# DSS_RCM register map
Vendor: Texas Instruments
Peripheral module from a debugger description file (folder awr2x44p).
Registers are 32-bit, read-write, no defined reset value unless marked. A register's access mark holds for its fields unless they carry their own. Offsets are as the file gives them; lines under a group give offsets from that group; [hi:lo] are bit positions; {n}, {i} and the like mark numbered series; 'fields as' and 'values as' point back to an identical list; <NAME> marks a mode.

## DSS_RCM
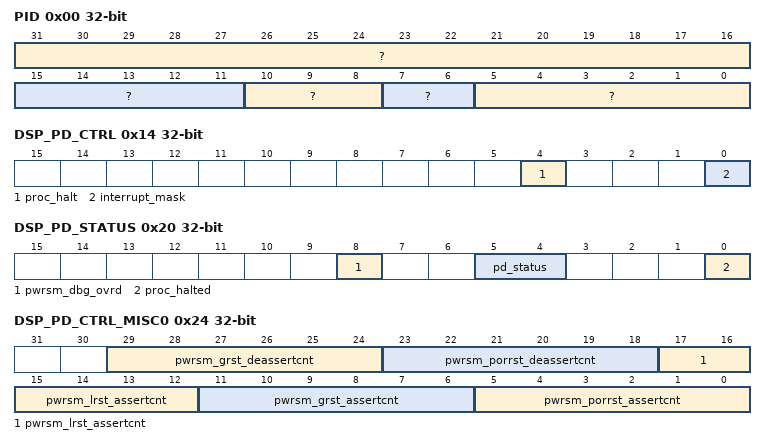
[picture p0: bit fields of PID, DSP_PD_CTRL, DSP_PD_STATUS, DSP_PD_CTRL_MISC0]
0x00 PID ro
  [31:16] ?, [15:11] ?, [10:8] ?, [7:6] ?, [5:0] ?
0x04 HW_REG0
  [31:0] hwreg — HW Reserved regiser
0x08 HW_REG1
  [31:0] hwreg — HW Reserved regiser
0x0C PREVIOUS_NAME
  [31:0] hwreg — HW Reserved regiser
0x10 HW_REG3
  [31:0] hwreg — HW Reserved regiser
0x14 DSP_PD_CTRL
  [4] proc_halt — Controls the unhalting on the processor during the power-up sequence Write 1 : The DSP is kept in halt state at the end of the power up sequence. The L2 memories can now be initialised and loaded before setting this bit to 0, unhalting the processor and begin execution Write 0 : The processor is unhalted at the end of the power up sequence. Here the assumption is the code is already downloaded in L2 and the processor can immediatey being execution on power up.
  [0] interrupt_mask — Masks interrupts to the DSP. Write 1 : Mask interrupts to the DSP before powering off the DSP. When masked, any interrupts are now stored in the Missed event register. Write 0 : Send the interrupts to the DSP after power on.
0x18 DSP_PD_TRIGGER_WAKUP
  [0] wakeup_trigger — Write pulse bit field: Trigger Power Up of the DSP. Write 1 : Triggers DSP power up sequence
0x1C DSP_PD_TRIGGER_SLEEP
  [0] sleep_trigger — Write pulse bit field: Trigger Power Down of the DSP. Write 1 : Triggers DSP power down sequence
0x20 DSP_PD_STATUS ro
  [8] pwrsm_dbg_ovrd — Status bit indicating if there is an override for the DSP from Debug SubSystem. 0 : No override from DebugSS 1 : Override from DebugSS
  [5:4] pd_status — Power Mode status of DSP 00 : Powered OFF 01 : Transitioning from OFF to ON state 10 : Transitioning from ON to OFF state 11 : Powered ON
  [0] proc_halted — Processor is halted
0x24 DSP_PD_CTRL_MISC0
  [29:24] pwrsm_grst_deassertcnt — TI Internal Feature No of cycles to wait after de-assertion of GRSTN during DSP Power-up sequence. Max allowed value is 31.
  [23:18] pwrsm_porrst_deassertcnt — TI Internal Feature No of cycles to wait after de-assertion of POR during DSP Power-up sequence. Max allowed value is 31.
  [17:12] pwrsm_lrst_assertcnt — TI Internal Feature No of cycles to wait after assertion of LRSTN during DSP Power-up sequence. Max allowed value is 31.
  [11:6] pwrsm_grst_assertcnt — TI Internal Feature No of cycles to wait after assertion of GRSTN during DSP Power-up sequence. Max allowed value is 31.
  [5:0] pwrsm_porrst_assertcnt — TI Internal Feature No of cycles to wait after assertion of POR during DSP Power-up sequence. Max allowed value is 31.
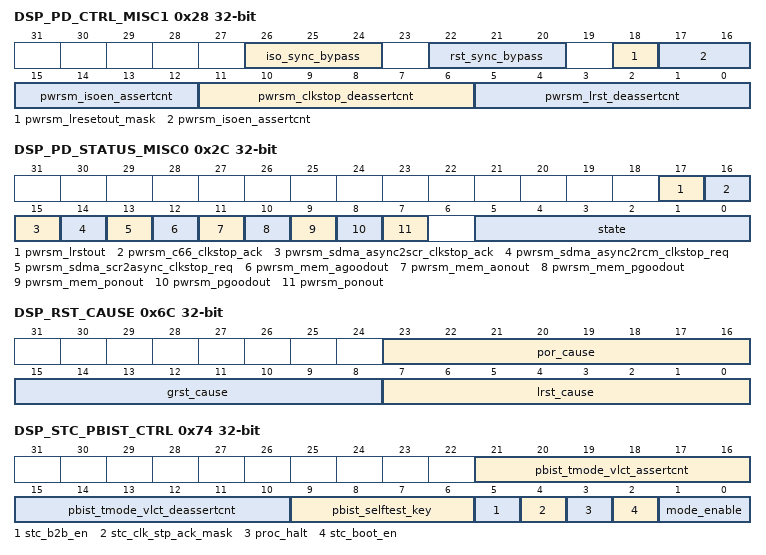
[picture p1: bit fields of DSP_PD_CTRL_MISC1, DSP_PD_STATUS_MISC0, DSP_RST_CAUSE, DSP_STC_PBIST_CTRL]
0x28 DSP_PD_CTRL_MISC1
  [26:24] iso_sync_bypass — HW RnD reserved. Do not Touch - Only for debug purpose
  [22:20] rst_sync_bypass — HW RnD reserved. Do not Touch - Only for debug purpose
  [18] pwrsm_lresetout_mask — TI Internal Feature 1:mask lresetout from DSPin FSM
  [17:12] pwrsm_isoen_assertcnt — TI Internal Feature No of cycles to wait after assertion of ISO_ENABLE during GEM power-down sequence. Max allowed value is 31.
  [11:6] pwrsm_clkstop_deassertcnt — TI Internal Feature No of cycles to wait after de-assertion of GEM_CLK_STOP_REQ during GEM Power-up sequence. Max allowed value is 31.
  [5:0] pwrsm_lrst_deassertcnt — TI Internal Feature No of cycles to wait after de-assertion of LRSTN during DSP Power-up sequence. Max allowed value is 31.
0x2C DSP_PD_STATUS_MISC0 ro
  [17] pwrsm_lrstout — TI Internal Feature Lreset output indication from GEM
  [16] pwrsm_c66_clkstop_ack — TI Internal Feature Clock stop request ack from GEM
  [15] pwrsm_sdma_async2scr_clkstop_ack — TI Internal Feature SDMA slave disable Done from clock stop ack from the master port of the async bridge present in the SDMA port.
  [14] pwrsm_sdma_async2rcm_clkstop_req — TI Internal Feature SDMA Slave disable Ack from Interconnect. This is from the clock stop req signal coming from the slave port of the async bridge in SDMA.
  [13] pwrsm_sdma_scr2async_clkstop_req — TI Internal Feature Clock Stop request from SCR to SDMA Async Bridge
  [12] pwrsm_mem_agoodout — TI Internal Feature Memory AGOOD Output from GEM (synchronized to Bus clock)
  [11] pwrsm_mem_aonout — TI Internal Feature Memory AON Output from GEM (synchronized to Bus clock)
  [10] pwrsm_mem_pgoodout — TI Internal Feature Memory PGOOD Output from DSP (synchronized to Bus clock)
  [9] pwrsm_mem_ponout — TI Internal Feature Memory PON Output from DSP (synchronized to Bus clock)
  [8] pwrsm_pgoodout — TI Internal Feature Logic PGOOD Output from DSP (synchronized to Bus clock)
  [7] pwrsm_ponout — TI Internal Feature Logic PON Output from DSP (synchronized to Bus clock)
  [5:0] state — This is the internal state of the DSP power State machine. Curretnly value of 13 needs to be polled to confirm we we can now download code to the L2 memory before unhalting the processor. Plan to change this in TPR and provide a single bit to poll on and move this to debug register since all the other states are irrelevant for SW
0x30 DSP_PD_WAKEUP_MASK0
  [31:0] wakeup_mask0 — Bit level mask for each of the wakeup source bits [31:0] 1 : Masked 0 : Unmasked
0x34 DSP_PD_WAKEUP_MASK1
  [31:0] wakeup_mask1 — Bit level mask for each of the wakeup source bits [63:32] 1 : Masked 0 : Unmasked.
0x38 DSP_PD_WAKEUP_MASK2
  [31:0] wakeup_mask2 — Bit level mask for each of the wakeup source bits [95:64] 1 : Masked 0 : Unmasked.
{0x3C+4i} DSP_PD_WAKEUP_STATUS{i} ro (i=0..2)
  [31:0] wakeup_status{i} — Wakeup source status bits [{32i+31}:{32i}]
{0x48+4i} DSP_PD_WAKEUP_STATUS{i}_CLR (i=0..2)
  [31:0] wakeup_status{i}_clr — Write pulse bit field: Clear bit for wakeup source status bits [{32i+31}:{32i}]. Write 0x1 to clear the corrsponding status bit : Its a wspecial access type, write to this field will generate a pulse
{0x54+4i} DSP_PD_MISSED_EVENT_MASK{i} (i=0..2)
  [31:0] missed_event_mask{i} — Bit level mask for each of the missed events before getting pushed into DSP. Corresponds to Event lines[{32i+31}:{32i}] 1 : Masked 0 : Unmasked.
0x60 DSP_PD_MISSED_EVENT_STATUS0 ro
  [31:0] missed_event_status0 — Missed events monitor status for interrupts [31:0]. Interrupts to DSP that are masked by INTERRUPT_MASK register field are captured in this register
0x64 DSP_PD_MISSED_EVENT_STATUS1 ro
  [31:0] missed_event_status1 — Missed events monitor status for interrupts [63:32] Interrupts to DSP that are masked by INTERRUPT_MASK register field are captured in this register
0x68 DSP_PD_MISSED_EVENT_STATUS2 ro
  [31:0] missed_event_status2 — Missed events monitor status for interrupts [95:64] Interrupts to DSP that are masked by INTERRUPT_MASK register field are captured in this register
0x6C DSP_RST_CAUSE ro
  [23:16] por_cause — DSP POR reset Bitwise Indication : Bit 0 : Por Reset Bit 1 : Sub system Reset from TOPRCM Bit 2 : Reset from DSS_RCM::DSS_DSP_RST_CTRL Bit 3 : Reset from Power FSM Bit 4 : Reset from STC FSM
  [15:8] grst_cause — DSP Greset Bitwise Indication : Bit 0 : Por Reset Bit 1 : Sub system Reset from TOPRCM Bit 2 : Reset from DSS_RCM::DSS_DSP_RST_CTRL Bit 3 : Reset from Power FSM Bit 4 : Reset from STC FSM
  [7:0] lrst_cause — DSP Lreset Bitwise Indication : Bit 0 : Por Reset Bit 1 : Sub system Reset from TOPRCM Bit 2 : Reset from DSS_RCM::DSS_DSP_RST_CTRL Bit 3 : Reset from Debugss Bit 4 : Reset from Power FSM Bit 5 : Reset from STC FSM
0x70 DSP_RST_CAUSE_CLR
  [0] clear — Write pulse bit field: Write 0x1 to clear the reset cause register for any previous resets : Its a wspecial access type, write to this field will generate a pulse
0x74 DSP_STC_PBIST_CTRL
  [21:16] pbist_tmode_vlct_assertcnt — No of clocks (in terms of 200 MHz DSPSS Bus clock) after asserting GEM TMODE VLCT signal before proceeding to the next state. Max allowed value is 31.
  [15:10] pbist_tmode_vlct_deassertcnt — No of clocks (in terms of 200 MHz DSPSS Bus clock) after De-asserting GEM TMODE VLCT signal before proceeding to the next state. Max allowed value is 31.
  [9:6] pbist_selftest_key — [4:1] DSP PBIST SELFTEST KEY = 4'b1010
  [5] stc_b2b_en — Enables back to Back STC.Needs to be set to 1 for self test
  [4] stc_clk_stp_ack_mask — Mask bit for ignoring the clock stop ack from GEM. This will be used for ignoring clock stop ack during boot-up. 1 --> Ignore clock stop ack from GEM. 0 --> Wait for clock stop ack from GEM after giving clock stop request.
  [3] proc_halt — Configuration to halt the state machine before the final de-assertion of LRST to enable program download. 1 --> Halt, 0 --> Proceed.
  [2] stc_boot_en — Enable GEM STC during GEM power UP
  [1:0] mode_enable — Enable for PBIST and STC. 00 - Reserved, 01 --> STC only 10 --> PBIST only 11 --> PBIST followed by STC
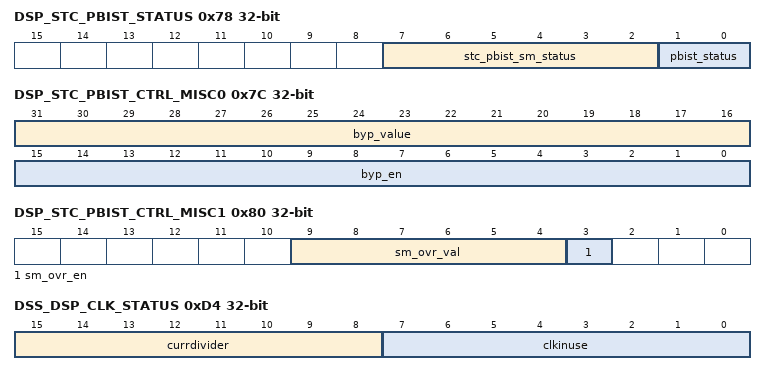
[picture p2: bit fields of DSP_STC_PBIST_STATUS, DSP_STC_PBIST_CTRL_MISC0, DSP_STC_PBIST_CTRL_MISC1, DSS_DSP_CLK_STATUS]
0x78 DSP_STC_PBIST_STATUS ro
  [7:2] stc_pbist_sm_status — PBIST status from GEM. undefined - Fail Indication undefined - Done indication
  [1:0] pbist_status — Current state of STC PBIST state machine
0x7C DSP_STC_PBIST_CTRL_MISC0
  [31:16] byp_value — DSP PBIST STC misc Control
  [15:0] byp_en — DSP PBIST STC misc Control
0x80 DSP_STC_PBIST_CTRL_MISC1
  [9:4] sm_ovr_val — TI Internal Register.Reserved for HW RnD
  [3] sm_ovr_en — TI Internal Register.Reserved for HW RnD
0x84 DSP_STC_PBIST_START
  [0] sm_trig — write pulse bit field: Write pulse bit field: Trigger pulse for the STC PBIST state machine. This is a self-clearing pulse. : Its a wspecial access type, write to this field will generate a pulse
0x88 DSP_STC_PBIST_STATUS_CLR
  [0] clear — Write pulse bit field: Clear bit for PBIST Status : Its a wspecial access type, write to this field will generate a pulse
0x8C DSS_DSP_CLK_SRC_SEL
  [11:0] clksrcsel — Select line for selecting source clock for DSS DSP. Data should be loaded as multibit. For example: if Clock source 0x5 should be selected then 0x555 should be configured to the register. Refer to TPR12 clock spec for source clock reference
0x90 DSS_HWA_CLK_SRC_SEL
  [2:0] clksrcsel — Select line for selecting source clock for DSS HWA. Data should be loaded as multibit. Write 3'b000 : TOPRCM_CR5_CLK Write 3'b111 : TOPRCM_SYS_CLK
0x94 DSS_RTIA_CLK_SRC_SEL
  [11:0] clksrcsel — Select line for selecting source clock for DSS_RTIA. Data should be loaded as multibit. For example: if Clock source 0x5 should be selected then 0x555 should be configured to the register. Refer to TPR12 clock spec for source clock reference
0x98 DSS_RTIB_CLK_SRC_SEL
  [11:0] clksrcsel — Select line for selecting source clock for DSS RTIB. Data should be loaded as multibit. For example: if Clock source 0x5 should be selected then 0x555 should be configured to the register. Refer to TPR12 clock spec for source clock reference
0x9C DSS_WDT_CLK_SRC_SEL
  [11:0] clksrcsel — Select line for selecting source clock for DSS Watchdog. Data should be loaded as multibit. For example: if Clock source 0x5 should be selected then 0x555 should be configured to the register. Refer to TPR12 clock spec for source clock reference
0xA0 DSS_SCIA_CLK_SRC_SEL
  [11:0] clksrcsel — Select line for selecting source clock for DSS SCIA. Data should be loaded as multibit. For example: if Clock source 0x5 should be selected then 0x555 should be configured to the register. Refer to TPR12 clock spec for source clock reference
0xA4 DSS_DSP_CLK_DIV_VAL
  [11:0] clkdiv — Divider value for DSS DSP selected clock. Data should be loaded as multibit. For example: if divider value of 0x5 should be selected then 0x555 should be configured to the register.
0xA8 DSS_RTIA_CLK_DIV_VAL
  [11:0] clkdiv — Divider value for DSS RTIA selected clock. Data should be loaded as multibit. For example: if divider value of 0x5 should be selected then 0x555 should be configured to the register.
0xAC DSS_RTIB_CLK_DIV_VAL
  [11:0] clkdiv — Divider value for DSS RTIB selected clock. Data should be loaded as multibit. For example: if divider value of 0x5 should be selected then 0x555 should be configured to the register.
0xB0 DSS_WDT_CLK_DIV_VAL
  [11:0] clkdiv — Divider value for DSS Watchdog selected clock. Data should be loaded as multibit. For example: if divider value of 0x5 should be selected then 0x555 should be configured to the register.
0xB4 DSS_SCIA_CLK_DIV_VAL
  [11:0] clkdiv — Divider value for DSS SCIA selected clock. Data should be loaded as multibit. For example: if divider value of 0x5 should be selected then 0x555 should be configured to the register.
0xB8 DSS_DSP_CLK_GATE
  [2:0] gated — Clock gatring config for DSS DSP. Data should be loaded as multibit. Write 3'b000 : Clock is ungated Write 3'b111 : Clock is gated
0xBC DSS_HWA_CLK_GATE
  [2:0] gated — Clock gatring config for DSS HWA Data should be loaded as multibit. Write 3'b000 : Clock is ungated Write 3'b111 : Clock is gated
0xC0 DSS_RTIA_CLK_GATE
  [2:0] gated — Clock gatring config for DSS RTA Data should be loaded as multibit. Write 3'b000 : Clock is ungated Write 3'b111 : Clock is gated
0xC4 DSS_RTIB_CLK_GATE
  [2:0] gated — Clock gatring config for DSS RTIB Data should be loaded as multibit. Write 3'b000 : Clock is ungated Write 3'b111 : Clock is gated
0xC8 DSS_WDT_CLK_GATE
  [2:0] gated — Clock gatring config for DSS Watchdog Data should be loaded as multibit. Write 3'b000 : Clock is ungated Write 3'b111 : Clock is gated
0xCC DSS_SCIA_CLK_GATE
  [2:0] gated — Clock gatring config for DSS SCIA Data should be loaded as multibit. Write 3'b000 : Clock is ungated Write 3'b111 : Clock is gated
0xD0 DSS_CBUFF_CLK_GATE
  [2:0] gated — Clock gating config for DSS CBUFF Data should be loaded as multibit. Write 3'b000 : Clock is ungated Write 3'b111 : Clock is gated
0xD4 DSS_DSP_CLK_STATUS ro
  [15:8] currdivider — Status shows the current divider value choosen for DSS DSP Clock
  [7:0] clkinuse — Status shows the source clock slected for DSS DSP Clock
0xD8 DSS_HWA_CLK_STATUS ro
  [1:0] clkinuse — Status shows the source clock slected for DSS HWA Clock
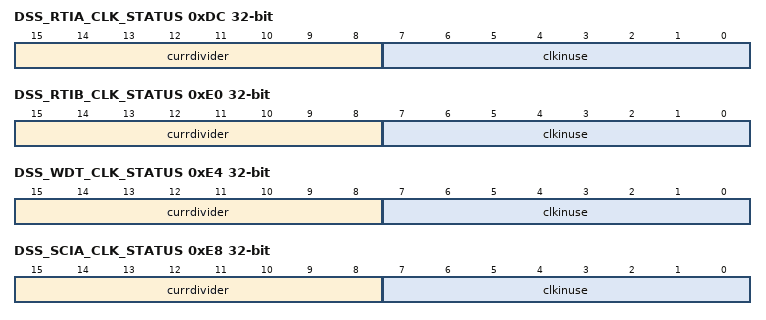
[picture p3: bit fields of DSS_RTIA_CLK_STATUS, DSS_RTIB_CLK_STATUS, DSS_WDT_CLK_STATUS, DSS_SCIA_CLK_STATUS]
0xDC DSS_RTIA_CLK_STATUS ro
  [15:8] currdivider — Status shows the current divider value choosen for DSS RTIA Clock
  [7:0] clkinuse — Status shows the source clock slected for DSS RTIA Clock
0xE0 DSS_RTIB_CLK_STATUS ro
  [15:8] currdivider — Status shows the current divider value choosen for DSS RTIB Clock
  [7:0] clkinuse — Status shows the source clock slected for DSS RTIB Clock
0xE4 DSS_WDT_CLK_STATUS ro
  [15:8] currdivider — Status shows the current divider value choosen for DSS Watchdog Clock
  [7:0] clkinuse — Status shows the source clock slected for DSS Watchdog Clock
0xE8 DSS_SCIA_CLK_STATUS ro
  [15:8] currdivider — Status shows the current divider value choosen for DSS SCIA Clock
  [7:0] clkinuse — Status shows the source clock slected for DSS SCIA Clock
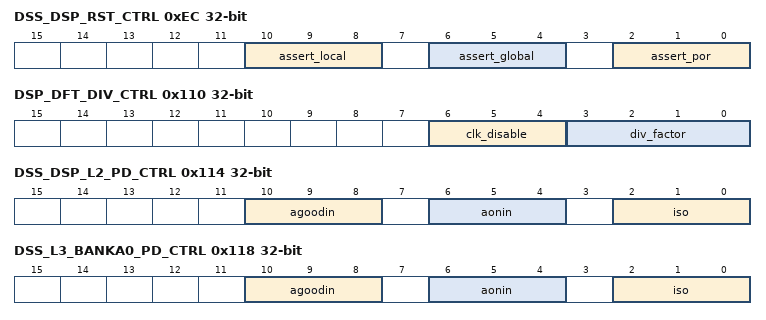
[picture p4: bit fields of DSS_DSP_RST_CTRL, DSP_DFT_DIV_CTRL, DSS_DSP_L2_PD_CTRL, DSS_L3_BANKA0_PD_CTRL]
0xEC DSS_DSP_RST_CTRL
  [10:8] assert_local — Local Reset control for DSS DSP Data should be loaded as multibit. Write 3'b000: Reset is not asserted by SW. There could be another reset source which could reset the module. Refer to RCM spec for more details Write 3'b111 : Reset is asserted by SW
  [6:4] assert_global — Global Reset control forDSS DSP Data should be loaded as multibit. Write 3'b000: Reset is not asserted by SW. There could be another reset source which could reset the module. Refer to RCM spec for more details Write 3'b111 : Reset is asserted by SW
  [2:0] assert_por — Power on Reset control for DSS DSP Data should be loaded as multibit. Write 3'b000: Reset is not asserted by SW. There could be another reset source which could reset the module. Refer to RCM spec for more details Write 3'b111 : Reset is asserted by SW
0xF0 DSS_ESM_RST_CTRL
  [2:0] assert — This feature is for debug purpose only. Software needs to ensure the state of Device/IP before configuring. Writing 3'b11 will assert reset for DSS ESM
0xF4 DSS_SCIA_RST_CTRL
  [2:0] assert — This feature is for debug purpose only. Software needs to ensure the state of Device/IP before configuring. Writing 3'b11 will assert reset for DSS SCIA
0xF8 DSS_RTIA_RST_CTRL
  [2:0] assert — This feature is for debug purpose only. Software needs to ensure the state of Device/IP before configuring. Writing 3'b11 will assert reset for DSS RTIA
0xFC DSS_RTIB_RST_CTRL
  [2:0] assert — This feature is for debug purpose only. Software needs to ensure the state of Device/IP before configuring. Writing 3'b11 will assert reset for DSS RTIB
0x100 DSS_WDT_RST_CTRL
  [2:0] assert — This feature is for debug purpose only. Software needs to ensure the state of Device/IP before configuring. Writing 3'b11 will assert reset for DSS Watchdog
0x104 DSS_DCCA_RST_CTRL
  [2:0] assert — This feature is for debug purpose only. Software needs to ensure the state of Device/IP before configuring. Writing 3'b11 will assert reset for DSS DCCA
0x108 DSS_DCCB_RST_CTRL
  [2:0] assert — This feature is for debug purpose only. Software needs to ensure the state of Device/IP before configuring. Writing 3'b11 will assert reset for DSS DCCB
0x10C DSS_MCRC_RST_CTRL
  [2:0] assert — This feature is for debug purpose only. Software needs to ensure the state of Device/IP before configuring. Writing 3'b11 will assert reset for DSS MCRC
0x110 DSP_DFT_DIV_CTRL
  [6:4] clk_disable — DSP DFT Control for clock_disable. Multibit implementation. Write 0x0 to enable Write 0x7 to diable
  [3:0] div_factor — DSP DFT Control for div factor
0x114 DSS_DSP_L2_PD_CTRL
  [10:8] agoodin — SW Control for <IP>_PD_CTRL Memory Array Power up CRTL1
  [6:4] aonin — SW Control for <IP>_PD_CTRL Memory Array Power up CRTL0
  [2:0] iso — SW Control for <IP>_PD_CTRL Isolation
0x118 DSS_L3_BANKA0_PD_CTRL
  fields as DSS_DSP_L2_PD_CTRL
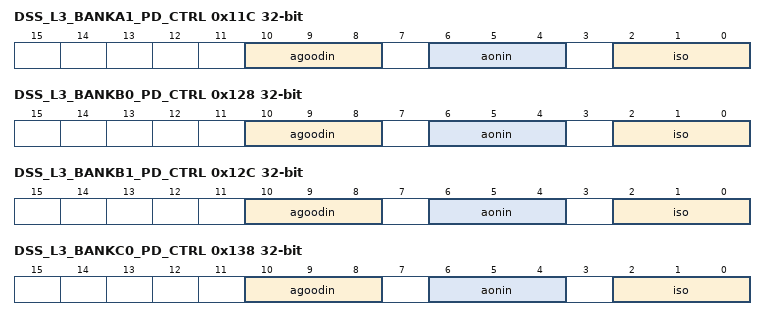
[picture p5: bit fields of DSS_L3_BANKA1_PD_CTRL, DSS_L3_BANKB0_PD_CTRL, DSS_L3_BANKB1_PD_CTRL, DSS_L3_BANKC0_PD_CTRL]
0x11C DSS_L3_BANKA1_PD_CTRL
  fields as DSS_DSP_L2_PD_CTRL
0x128 DSS_L3_BANKB0_PD_CTRL
  fields as DSS_DSP_L2_PD_CTRL
0x12C DSS_L3_BANKB1_PD_CTRL
  fields as DSS_DSP_L2_PD_CTRL
0x138 DSS_L3_BANKC0_PD_CTRL
  fields as DSS_DSP_L2_PD_CTRL
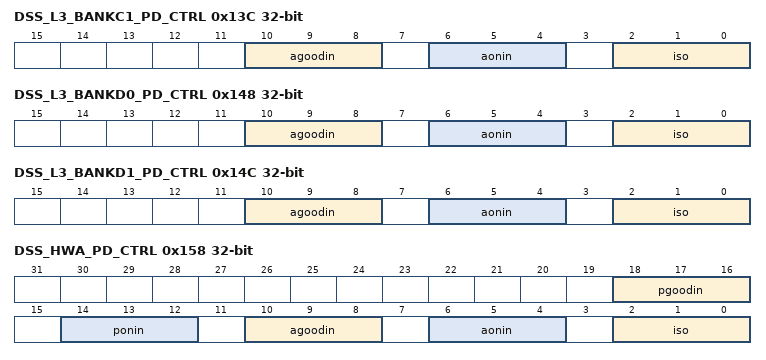
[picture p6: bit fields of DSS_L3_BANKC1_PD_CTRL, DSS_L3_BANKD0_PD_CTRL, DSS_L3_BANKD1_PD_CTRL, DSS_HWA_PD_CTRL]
0x13C DSS_L3_BANKC1_PD_CTRL
  fields as DSS_DSP_L2_PD_CTRL
0x148 DSS_L3_BANKD0_PD_CTRL
  fields as DSS_DSP_L2_PD_CTRL
0x14C DSS_L3_BANKD1_PD_CTRL
  fields as DSS_DSP_L2_PD_CTRL
0x158 DSS_HWA_PD_CTRL
  [18:16] pgoodin — SW Control for <IP>_PD_CTRL Power up CRTL1
  [14:12] ponin — SW Control for <IP>_PD_CTRL Power up CRTL0
  [10:8] agoodin — SW Control for <IP>_PD_CTRL Memory Array Power up CRTL1
  [6:4] aonin — SW Control for <IP>_PD_CTRL Memory Array Power up CRTL0
  [2:0] iso — SW Control for <IP>_PD_CTRL Isolation
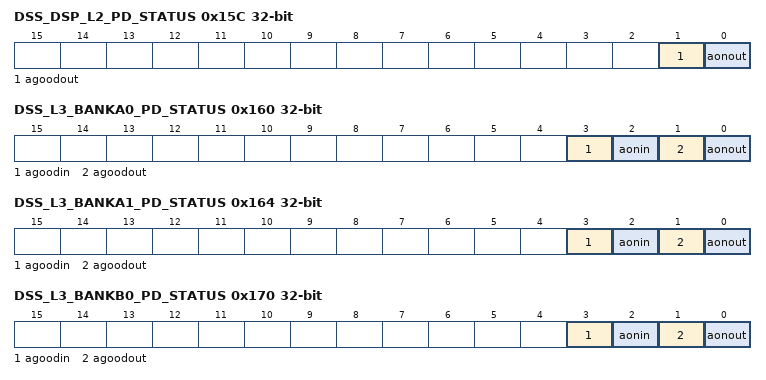
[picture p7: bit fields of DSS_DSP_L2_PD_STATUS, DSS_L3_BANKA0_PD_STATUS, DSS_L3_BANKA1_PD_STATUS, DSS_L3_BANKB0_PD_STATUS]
0x15C DSS_DSP_L2_PD_STATUS ro
  [1] agoodout — Status for <IP>_PD_CTRL Memory Array Power up CRTL1
  [0] aonout — Status for <IP>_PD_CTRL Memory Array Power up CRTL0
0x160 DSS_L3_BANKA0_PD_STATUS ro
  [3] agoodin — Status for sticky control <IP>_PD_CTRL Memory Array Power up CRTL1
  [2] aonin — Status for sticky control <IP>_PD_CTRL Memory Array Power up CRTL0
  [1] agoodout — Status for <IP>_PD_CTRL Memory Array Power up CRTL1
  [0] aonout — Status for <IP>_PD_CTRL Memory Array Power up CRTL0
0x164 DSS_L3_BANKA1_PD_STATUS ro
  fields as DSS_L3_BANKA0_PD_STATUS
0x170 DSS_L3_BANKB0_PD_STATUS ro
  fields as DSS_L3_BANKA0_PD_STATUS
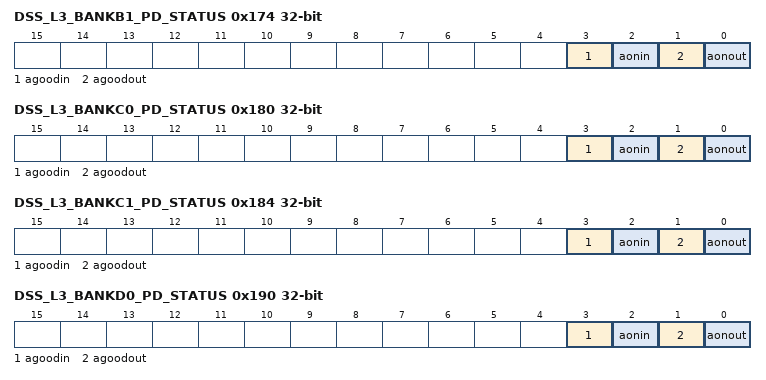
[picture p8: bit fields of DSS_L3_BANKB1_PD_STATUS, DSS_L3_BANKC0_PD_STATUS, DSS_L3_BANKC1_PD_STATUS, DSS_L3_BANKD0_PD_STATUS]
0x174 DSS_L3_BANKB1_PD_STATUS ro
  fields as DSS_L3_BANKA0_PD_STATUS
0x180 DSS_L3_BANKC0_PD_STATUS ro
  fields as DSS_L3_BANKA0_PD_STATUS
0x184 DSS_L3_BANKC1_PD_STATUS ro
  fields as DSS_L3_BANKA0_PD_STATUS
0x190 DSS_L3_BANKD0_PD_STATUS ro
  fields as DSS_L3_BANKA0_PD_STATUS
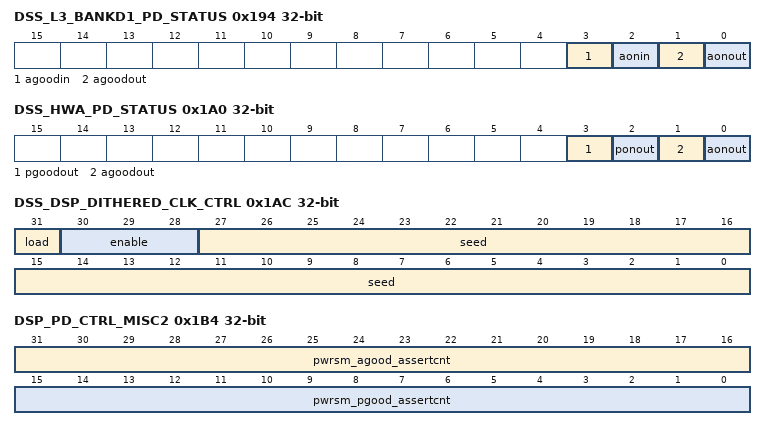
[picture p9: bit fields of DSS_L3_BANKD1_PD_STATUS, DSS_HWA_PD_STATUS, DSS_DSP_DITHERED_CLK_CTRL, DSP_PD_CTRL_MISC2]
0x194 DSS_L3_BANKD1_PD_STATUS ro
  fields as DSS_L3_BANKA0_PD_STATUS
0x1A0 DSS_HWA_PD_STATUS ro
  [3] pgoodout — Status for <IP>_PD_CTRL Power up CRTL1
  [2] ponout — Status for <IP>_PD_CTRL Power up CRTL0
  [1] agoodout — Status for <IP>_PD_CTRL Memory Array Power up CRTL1
  [0] aonout — Status for <IP>_PD_CTRL Memory Array Power up CRTL0
0x1A4 DSS_DSP_TRCCLK_DIVRATIO
  [3:0] divratio — DSP Trace Clock Divide Ratio
0x1A8 DSS_DSP_TCLK_DIVRATIO
  [3:0] divratio — DSP TCLK Divide Ratio
0x1AC DSS_DSP_DITHERED_CLK_CTRL
  [31] load — Write pulse bit field: DSP Dithered Clock LFSR Load
  [30:28] enable — DSP Dithered Clock Enable. Write 3'b000 : Disabled Write 3'b111 : Enabled
  [27:0] seed — DSP Dithered Clock LFSR Seed
0x1B0 DSS_L3_PD_CTRL_STICKYBIT
  [2:0] set — Sticky bit for DSS L3 PD CTRL. Write 3'b111 to lock the configuration of DSS_L3_BANK*_PD_CTRL. Once this field is writen, there is no impact of changing the value of aonin and agoodin fields in DSS_L3_BANK*_PD_CTRL registers
0x1B4 DSP_PD_CTRL_MISC2
  [31:16] pwrsm_agood_assertcnt — Value of agood asertion delay
  [15:0] pwrsm_pgood_assertcnt — Value of pgood asertion delay
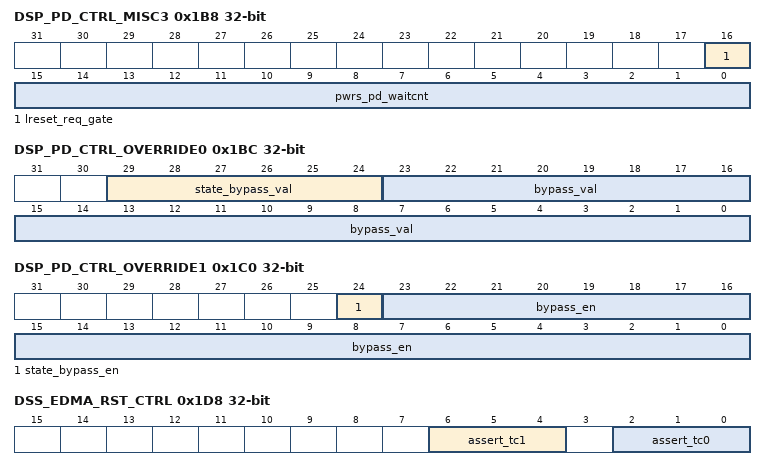
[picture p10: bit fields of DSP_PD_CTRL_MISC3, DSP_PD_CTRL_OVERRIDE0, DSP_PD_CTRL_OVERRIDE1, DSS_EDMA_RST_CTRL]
0x1B8 DSP_PD_CTRL_MISC3
  [16] lreset_req_gate — Gate the lreset request from GEM. For debug purpose.
  [15:0] pwrs_pd_waitcnt — Value of power down wait delay
0x1BC DSP_PD_CTRL_OVERRIDE0
  [29:24] state_bypass_val — DSS DSP power FSM state bypass control. For debug pupose.
  [23:0] bypass_val — DSS DSP power FSM bypass control. For debug pupose.
0x1C0 DSP_PD_CTRL_OVERRIDE1
  [24] state_bypass_en — DSS DSP power FSM state bypass control enable.For debug pupose.
  [23:0] bypass_en — DSS DSP power FSM bypass control enable.For debug pupose.
0x1C4 DSP_PD_CTRL_OVERRIDE2
  [2:0] override_enable — DSS DSP power FSM override enable .For debug pupose.
0x1C8 DSS_HWA_RST_CTRL
  [2:0] assert — This register is for Debug Purposes only. Reset control for DSS HWA Data should be loaded as multibit. Write 3'b000: Reset is not asserted by SW. There could be another reset source which could reset the module. Refer to RCM spec for more details Write 3'b111 : Reset is asserted by SW
0x1CC DSS_HWA_RST_CTRL
  [2:0] assert — This register is for Debug Purposes only. Reset control for DSS TPCCA Data should be loaded as multibit. Write 3'b000: Reset is not asserted by SW. There could be another reset source which could reset the module. Refer to RCM spec for more details Write 3'b111 : Reset is asserted by SW
0x1D0 DSS_EDMA_RST_CTRL
  [2:0] assert — This register is for Debug Purposes only. Reset control for DSS TPCCB Data should be loaded as multibit. Write 3'b000: Reset is not asserted by SW. There could be another reset source which could reset the module. Refer to RCM spec for more details Write 3'b111 : Reset is asserted by SW
0x1D4 DSS_EDMA_RST_CTRL
  [2:0] assert — This register is for Debug Purposes only. Reset control for DSS TPCCC Data should be loaded as multibit. Write 3'b000: Reset is not asserted by SW. There could be another reset source which could reset the module. Refer to RCM spec for more details Write 3'b111 : Reset is asserted by SW
0x1D8 DSS_EDMA_RST_CTRL
  [6:4] assert_tc1 — This register is for Debug Purposes only. Reset control for DSS TPTCA1 Data should be loaded as multibit. Write 3'b000: Reset is not asserted by SW. There could be another reset source which could reset the module. Refer to RCM spec for more details Write 3'b111 : Reset is asserted by SW
  [2:0] assert_tc0 — This register is for Debug Purposes only. Reset control for DSS TPTCA0 Data should be loaded as multibit. Write 3'b000: Reset is not asserted by SW. There could be another reset source which could reset the module. Refer to RCM spec for more details Write 3'b111 : Reset is asserted by SW
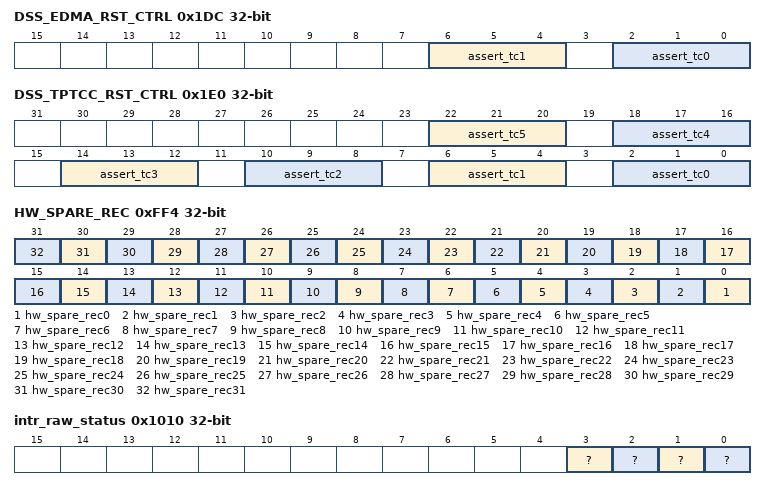
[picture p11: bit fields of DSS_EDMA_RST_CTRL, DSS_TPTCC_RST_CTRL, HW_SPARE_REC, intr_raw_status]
0x1DC DSS_EDMA_RST_CTRL
  [6:4] assert_tc1 — This register is for Debug Purposes only. Reset control for DSS TPTCB1 Data should be loaded as multibit. Write 3'b000: Reset is not asserted by SW. There could be another reset source which could reset the module. Refer to RCM spec for more details Write 3'b111 : Reset is asserted by SW
  [2:0] assert_tc0 — This register is for Debug Purposes only. Reset control for DSS TPTCB0 Data should be loaded as multibit. Write 3'b000: Reset is not asserted by SW. There could be another reset source which could reset the module. Refer to RCM spec for more details Write 3'b111 : Reset is asserted by SW
0x1E0 DSS_TPTCC_RST_CTRL
  [22:20] assert_tc5 — This register is for Debug Purposes only. Reset control for DSS TPTCC1 Data should be loaded as multibit. Write 3'b000: Reset is not asserted by SW. There could be another reset source which could reset the module. Refer to RCM spec for more details Write 3'b111 : Reset is asserted by SW
  [18:16] assert_tc4 — This register is for Debug Purposes only. Reset control for DSS TPTCC0 Data should be loaded as multibit. Write 3'b000: Reset is not asserted by SW. There could be another reset source which could reset the module. Refer to RCM spec for more details Write 3'b111 : Reset is asserted by SW
  [14:12] assert_tc3 — This register is for Debug Purposes only. Reset control for DSS TPTCC1 Data should be loaded as multibit. Write 3'b000: Reset is not asserted by SW. There could be another reset source which could reset the module. Refer to RCM spec for more details Write 3'b111 : Reset is asserted by SW
  [10:8] assert_tc2 — This register is for Debug Purposes only. Reset control for DSS TPTCC0 Data should be loaded as multibit. Write 3'b000: Reset is not asserted by SW. There could be another reset source which could reset the module. Refer to RCM spec for more details Write 3'b111 : Reset is asserted by SW
  [6:4] assert_tc1 — This register is for Debug Purposes only. Reset control for DSS TPTCC1 Data should be loaded as multibit. Write 3'b000: Reset is not asserted by SW. There could be another reset source which could reset the module. Refer to RCM spec for more details Write 3'b111 : Reset is asserted by SW
  [2:0] assert_tc0 — This register is for Debug Purposes only. Reset control for DSS TPTCC0 Data should be loaded as multibit. Write 3'b000: Reset is not asserted by SW. There could be another reset source which could reset the module. Refer to RCM spec for more details Write 3'b111 : Reset is asserted by SW
{0xFD0+4i} HW_SPARE_RW{i} (i=0..3)
  [31:0] hw_spare_rw{i} — Reserved for HW R&D
{0xFE0+4i} HW_SPARE_RO{i} ro (i=0..3)
  [31:0] hw_spare_ro{i} — Reserved for HW R&D
0xFF0 HW_SPARE_WPH
  [31:0] hw_spare_wph — write pulse bit field:Reserved for HW R&D
0xFF4 HW_SPARE_REC
  [n] hw_spare_rec{n} (n=0..31) — Rising Edge Capture reg (write 1 to clear): Reserved for HW R&D
0x1008 LOCK0_KICK0 — - KICK0 component
  [31:0] ?
0x100C LOCK0_KICK1 — - KICK1 component
  [31:0] ?
0x1010 intr_raw_status — Interrupt Raw Status/Set Register
  [3] ? — Proxy0 access violation error. Raw status is read. Write a 1 to set the status. Writing a 0 has no effect.
  [2] ? — Kick access violation error. Raw status is read. Write a 1 to set the status. Writing a 0 has no effect.
  [1] ? — Addressing violation error. Raw status is read. Write a 1 to set the status. Writing a 0 has no effect.
  [0] ? — Protection violation error. Raw status is read. Write a 1 to set the status. Writing a 0 has no effect.
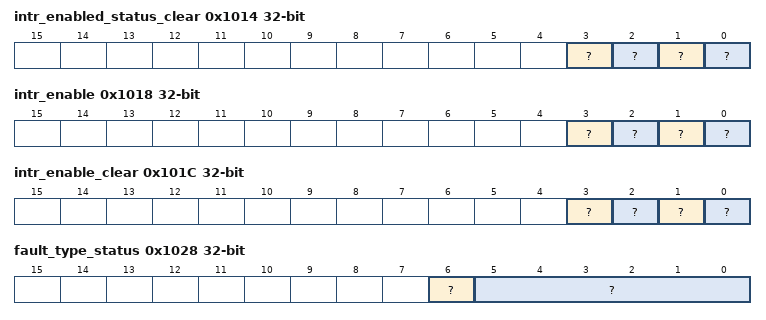
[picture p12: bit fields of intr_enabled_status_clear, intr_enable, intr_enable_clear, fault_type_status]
0x1014 intr_enabled_status_clear — Interrupt Enabled Status/Clear register
  [3] ? — Proxy0 access violation error. Enabled status is read. Write a 1 to clear the status. Writing a 0 has no effect.
  [2] ? — Kick access violation error. Enabled status is read. Write a 1 to clear the status. Writing a 0 has no effect.
  [1] ? — Addressing violation error. Enabled status is read. Write a 1 to clear the status. Writing a 0 has no effect.
  [0] ? — Protection violation error. Enabled status is read. Write a 1 to clear the status. Writing a 0 has no effect.
0x1018 intr_enable — Interrupt Enable register
  [3] ? — Proxy0 access violation error enable. Write a 1 to set the enable. Writing a 0 has no effect.
  [2] ? — Kick access violation error enable. Write a 1 to set the enable. Writing a 0 has no effect.
  [1] ? — Addressing violation error enable. Write a 1 to set the enable. Writing a 0 has no effect.
  [0] ? — Protection violation error enable. Write a 1 to set the enable. Writing a 0 has no effect.
0x101C intr_enable_clear — Interrupt Enable Clear register
  [3] ? — Proxy0 access violation error enable clear. Write a 1 to clear the enable. Writing a 0 has no effect.
  [2] ? — Kick access violation error enable clear. Write a 1 to clear the enable. Writing a 0 has no effect.
  [1] ? — Addressing violation error enable clear. Write a 1 to clear the enable. Writing a 0 has no effect.
  [0] ? — Protection violation error enable clear. Write a 1 to clear the enable. Writing a 0 has no effect.
0x1020 eoi
  [7:0] ? — EOI vector value. Write this with interrupt distribution value in the chip.
0x1024 fault_address ro
  [31:0] ? — Fault Address.
0x1028 fault_type_status ro
  [6] ? — Non-secure access.
  [5:0] ? — Fault Type 10_0000 = Supervisor read fault - priv = 1 dir = 1 dtype != 1 01_0000 = Supervisor write fault - priv = 1 dir = 0 00_1000 = Supervisor execute fault - priv = 1 dir = 1 dtype = 1 00_0100 = User read fault - priv = 0 dir = 1 dtype = 1 00_0010 = User write fault - priv = 0 dir = 0 00_0001 = User execute fault - priv = 0 dir = 1 dtype = 1 00_0000 = No fault
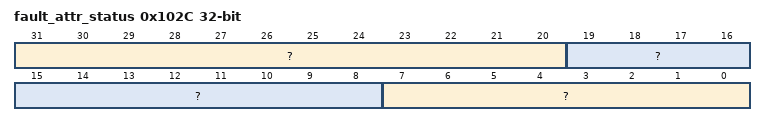
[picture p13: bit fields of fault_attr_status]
0x102C fault_attr_status ro — Fault Attribute Status register
  [31:20] ? — XID.
  [19:8] ? — Route ID.
  [7:0] ? — Privilege ID.
0x1030 fault_clear wo
  [0] ? — Fault clear. Writing a 1 clears the current fault. Writing a 0 has no effect.
